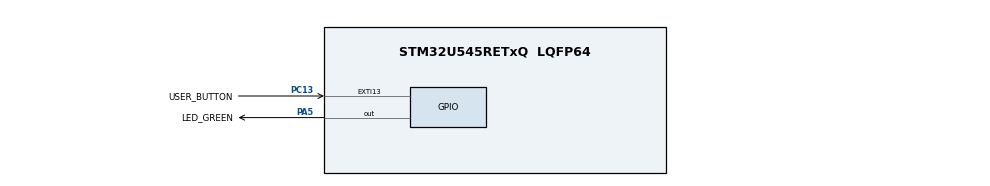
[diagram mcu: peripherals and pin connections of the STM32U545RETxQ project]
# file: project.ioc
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CORTEX_M33_NS.userName=CORTEX_M33
Mcu.Family=STM32U5
Mcu.Name=STM32U545RETxQ
Mcu.Package=LQFP64
NVIC.PriorityGroup=NVIC_PRIORITYGROUP_4
NVIC.TimeBase=None
PA5.GPIO_Label=LED_GREEN
PA5.GPIO_PuPd=GPIO_PULLUP
PA5.GPIO_Speed=GPIO_SPEED_FREQ_HIGH
PA5.Signal=GPIO_Output
PC13.GPIO_Label=USER_BUTTON
PC13.GPIO_ModeDefaultEXTI=GPIO_MODE_IT_FALLING
PC13.GPIO_PuPd=GPIO_PULLDOWN
PC13.Signal=GPXTI13
PWR.PowerMode=PWR_SMPS_SUPPLY
ProjectManager.HeapSize=0x200
ProjectManager.StackSize=0x400
ProjectManager.TargetToolchain=STM32CubeIDE
RCC.ADCFreq_Value=16000000
RCC.DACCLockSelectionVirtual=RCC_DAC1CLKSOURCE_LSI
RCC.DACCLockSelectionVirtualString=RCC_DAC1CLKSOURCE_LSI
RCC.EPOD_VALUE=4000000
RCC.HSE_VALUE=16000000
RCC.HSI48_VALUE=48000000
RCC.HSI_VALUE=16000000
RCC.LSE_VALUE=32768
RCC.LSIDIV_VALUE=32000
RCC.MSI_VALUE=4000000
RCC.USBFreq_Value=48000000
RCC.VCOOutputFreq_Value=516000000
VP_ICACHE_VS_ICACHE.Mode=DirectMappedCache
VP_LPBAMQUEUE_VS_QUEUE.Mode=QUEUEMODE
VP_LPBAM_VS_SIG1.Mode=SmartRun
VP_LPBAM_VS_SIG4.Mode=LPDMA1
VP_MEMORYMAP_VS_MEMORYMAP.Mode=CurAppReg
VP_NUCLEO-U545RE-Q_VS_BSP_COMMON.Mode=COMMON
VP_PWR_VS_LPOM.Mode=PowerOptimisation
VP_PWR_VS_SECSignals.Mode=Security/Privilege
VP_SYS_VS_None.Mode=None
board=NUCLEO-U545RE-Q

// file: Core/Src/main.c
/* USER CODE BEGIN Header */
/**
  ******************************************************************************
  * @file           : main.c
  * @brief          : Main program body
  ******************************************************************************
  * @attention
  *
  * Copyright (c) 2025 STMicroelectronics.
  * All rights reserved.
  *
  * This software is licensed under terms that can be found in the LICENSE file
  * in the root directory of this software component.
  * If no LICENSE file comes with this software, it is provided AS-IS.
  *
  ******************************************************************************
  */
/* USER CODE END Header */
#include "main.h"

void SystemClock_Config(void);
static void SystemPower_Config(void);
static void MX_GPIO_Init(void);
static void MX_ICACHE_Init(void);

int main(void)
{

  /* MCU Configuration--------------------------------------------------------*/

  /* Reset of all peripherals, Initializes the Flash interface and the Systick. */
  HAL_Init();

  /* Enable PWR clock interface */

  LL_AHB3_GRP1_EnableClock(LL_AHB3_GRP1_PERIPH_PWR);

  /* Configure the System Power */
  SystemPower_Config();

  /* Configure the system clock */
  SystemClock_Config();

  /* Initialize all configured peripherals */
  MX_GPIO_Init();
  MX_ICACHE_Init();
  /* USER CODE BEGIN 2 */
    return QP_run(); // run the QP application (should not return)
  /* USER CODE END 2 */

  /* Infinite loop */
  while (1)
  {

  }
}

void SystemClock_Config(void)
{
  LL_FLASH_SetLatency(LL_FLASH_LATENCY_0);
  while(LL_FLASH_GetLatency()!= LL_FLASH_LATENCY_0)
  {
  }

  LL_PWR_SetRegulVoltageScaling(LL_PWR_REGU_VOLTAGE_SCALE4);
  while (LL_PWR_IsActiveFlag_VOS() == 0)
  {
  }
  LL_RCC_MSIS_Enable();

   /* Wait till MSIS is ready */
  while(LL_RCC_MSIS_IsReady() != 1)
  {
  }

  LL_RCC_MSI_EnableRangeSelection();
  LL_RCC_MSIS_SetRange(LL_RCC_MSISRANGE_4);
  LL_RCC_MSI_SetCalibTrimming(16, LL_RCC_MSI_OSCILLATOR_1);
  LL_RCC_SetSysClkSource(LL_RCC_SYS_CLKSOURCE_MSIS);

   /* Wait till System clock is ready */
  while(LL_RCC_GetSysClkSource() != LL_RCC_SYS_CLKSOURCE_STATUS_MSIS)
  {
  }

  LL_RCC_SetAHBPrescaler(LL_RCC_SYSCLK_DIV_1);
  LL_RCC_SetAPB1Prescaler(LL_RCC_APB1_DIV_1);
  LL_RCC_SetAPB2Prescaler(LL_RCC_APB2_DIV_1);
  LL_RCC_SetAPB3Prescaler(LL_RCC_APB3_DIV_1);
  LL_SetSystemCoreClock(4000000);

   /* Update the time base */
  if (HAL_InitTick (TICK_INT_PRIORITY) != HAL_OK)
  {
    Error_Handler();
  }
}

/**
  * @brief Power Configuration
  * @retval None
  */
static void SystemPower_Config(void)
{

  /*
   * Switch to SMPS regulator instead of LDO
   */
  LL_PWR_SetRegulatorSupply(LL_PWR_SMPS_SUPPLY);

  while(LL_PWR_IsActiveFlag_REGULATOR()!=1)
  {
  }
}

static void MX_ICACHE_Init(void)
{

  /** Enable instruction cache in 1-way (direct mapped cache)
  */
  LL_ICACHE_SetMode(LL_ICACHE_1WAY);
  LL_ICACHE_Enable();

}

static void MX_GPIO_Init(void)
{
  LL_EXTI_InitTypeDef EXTI_InitStruct = {0};
  LL_GPIO_InitTypeDef GPIO_InitStruct = {0};

  /* GPIO Ports Clock Enable */
  LL_AHB2_GRP1_EnableClock(LL_AHB2_GRP1_PERIPH_GPIOC);
  LL_AHB2_GRP1_EnableClock(LL_AHB2_GRP1_PERIPH_GPIOA);

  /**/
  LL_GPIO_ResetOutputPin(LED_GREEN_GPIO_Port, LED_GREEN_Pin);

  /**/
  LL_EXTI_SetEXTISource(LL_EXTI_EXTI_PORTC, LL_EXTI_EXTI_LINE13);

  /**/
  EXTI_InitStruct.Line_0_31 = LL_EXTI_LINE_13;
  EXTI_InitStruct.LineCommand = ENABLE;
  EXTI_InitStruct.Mode = LL_EXTI_MODE_IT;
  EXTI_InitStruct.Trigger = LL_EXTI_TRIGGER_FALLING;
  LL_EXTI_Init(&EXTI_InitStruct);

  /**/
  LL_GPIO_SetPinPull(USER_BUTTON_GPIO_Port, USER_BUTTON_Pin, LL_GPIO_PULL_DOWN);

  /**/
  LL_GPIO_SetPinMode(USER_BUTTON_GPIO_Port, USER_BUTTON_Pin, LL_GPIO_MODE_INPUT);

  /**/
  GPIO_InitStruct.Pin = LED_GREEN_Pin;
  GPIO_InitStruct.Mode = LL_GPIO_MODE_OUTPUT;
  GPIO_InitStruct.Speed = LL_GPIO_SPEED_FREQ_HIGH;
  GPIO_InitStruct.OutputType = LL_GPIO_OUTPUT_PUSHPULL;
  GPIO_InitStruct.Pull = LL_GPIO_PULL_UP;
  LL_GPIO_Init(LED_GREEN_GPIO_Port, &GPIO_InitStruct);

}

void Error_Handler(void)
{
  __disable_irq();
  while (1)
  {
  }
}
